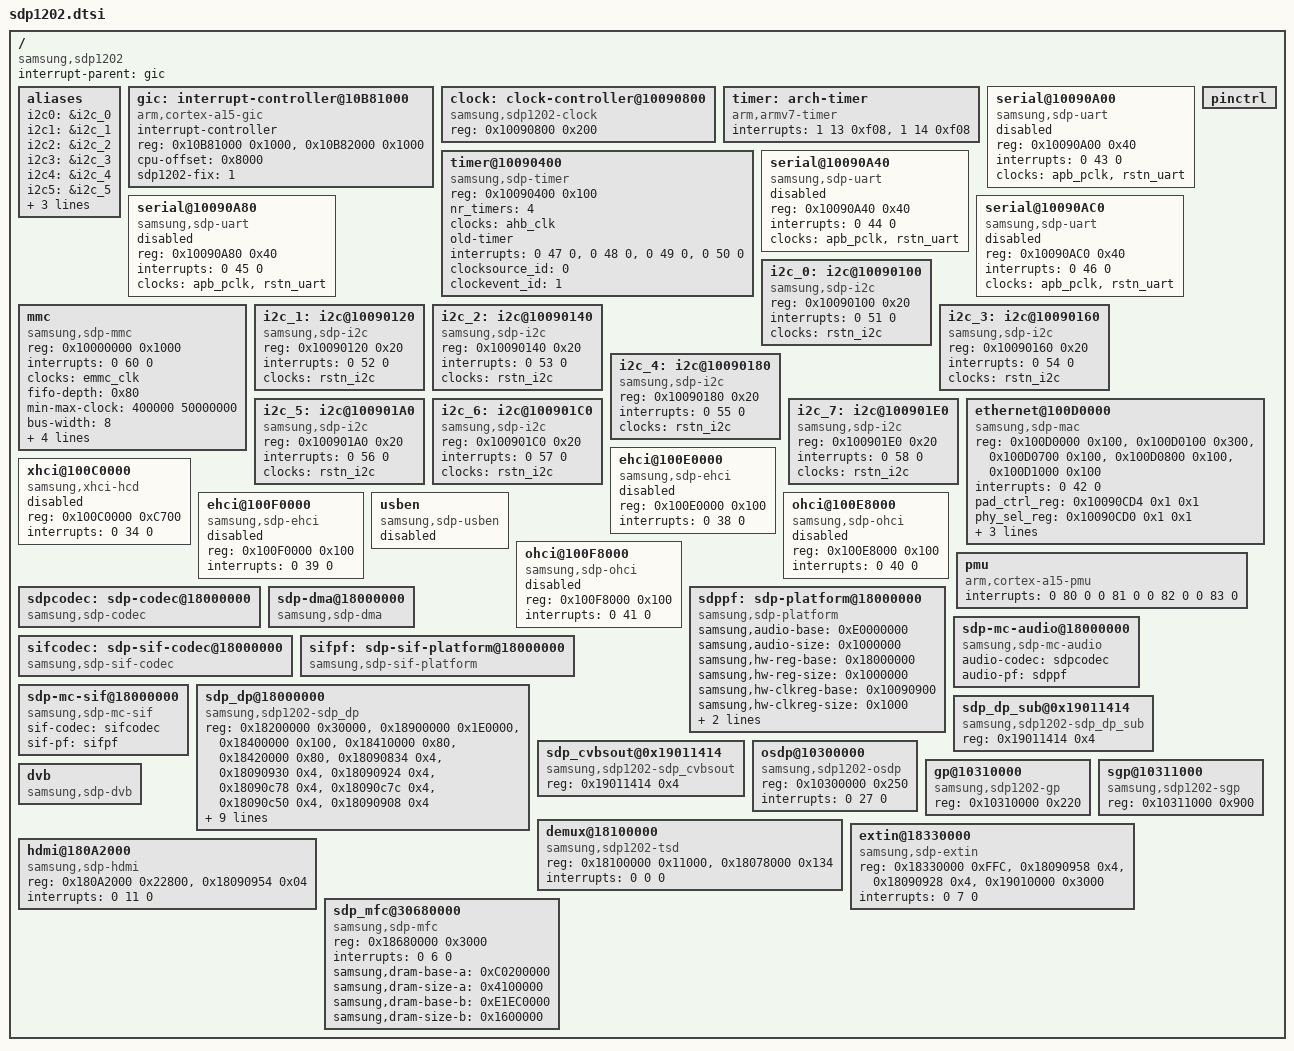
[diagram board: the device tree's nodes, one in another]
/*
 * Copyright (C) 2013 Samsung Electronics Co.Ltd
 *
 * This program is free software; you can redistribute it and/or modify
 * it under the terms of the GNU General Public License version 2 as
 * published by the Free Software Foundation.
 */

#include "sdp.dtsi"
#include "sdp1202-clocks.dtsi"
#include "sdp1202-pinctrl.dtsi"

/ {
	compatible = "samsung,sdp1202";

	interrupt-parent = <&gic>;

	aliases {
		i2c0 = &i2c_0;
		i2c1 = &i2c_1;
		i2c2 = &i2c_2;
		i2c3 = &i2c_3;
		i2c4 = &i2c_4;
		i2c5 = &i2c_5;
		i2c6 = &i2c_6;
		i2c7 = &i2c_7;
		i2c8 = &i2c_15;
	};


	gic: interrupt-controller@10B81000 {
		compatible = "arm,cortex-a15-gic";
		interrupt-controller;
		#interrupt-cells = <3>;
		reg = <0x10B81000 0x1000>, <0x10B82000 0x1000>;
		cpu-offset = <0x8000>;
		sdp1202-fix = <1>;
	};

	clock: clock-controller@10090800 {
		compatible = "samsung,sdp1202-clock";
		reg = <0x10090800 0x200>;
		#clock-cells = <1>;
	};

	timer: arch-timer {
		compatible = "arm,armv7-timer";
		interrupts = <1 13 0xf08>, 
					 <1 14 0xf08>;		    
	};

	timer@10090400 {
		compatible = "samsung,sdp-timer";
		reg = <0x10090400 0x100>;
		nr_timers = <4>;
		clocks = <&ahb_clk>;
		old-timer;
		clock-names = "ahb_clk";
		interrupts = <0 47 0>, <0 48 0>, <0 49 0>, <0 50 0>;
		clocksource_id = <0>;
		clockevent_id = <1>;
	};

	serial@10090A00 {
		compatible = "samsung,sdp-uart";
		reg = <0x10090A00 0x40>;
		interrupts = <0 43 0>;
		clocks = <&apb_pclk>, <&rstn_uart>;
		clock-names = "ahb_clk", "rstn_uart";
		status = "disabled";
	};

	serial@10090A40 {
		compatible = "samsung,sdp-uart";
		reg = <0x10090A40 0x40>;
		interrupts = <0 44 0>;
		clocks = <&apb_pclk>, <&rstn_uart>;
		clock-names = "ahb_clk", "rstn_uart";
		status = "disabled";
	};


	serial@10090A80 {
		compatible = "samsung,sdp-uart";
		reg = <0x10090A80 0x40>;
		interrupts = <0 45 0>;
		clocks = <&apb_pclk>, <&rstn_uart>;
		clock-names = "ahb_clk", "rstn_uart";
		status = "disabled";
	};


	serial@10090AC0 {
		compatible = "samsung,sdp-uart";
		reg = <0x10090AC0 0x40>;
		interrupts = <0 46 0>;
		clocks = <&apb_pclk>, <&rstn_uart>;
		clock-names = "ahb_clk", "rstn_uart";
		status = "disabled";
	};

	pinctrl{
		status = "okay";
	};
	
	mmc {
		compatible = "samsung,sdp-mmc";
		reg = <0x10000000 0x1000>;
		interrupts = <0 60 0>;
		clocks = <&emmc_clk>;
		clock-names = "emmc_clk";
		fifo-depth = <0x80>;
		min-max-clock = <400000 50000000>;

		//initregs = <0x0 0x0 0x0>;

		bus-width=<8>;
		//force-pio-mode;
		hw-reset;

		/* Host Caps */
		non-removable;
		//bus-width-test;
		highspeed;
		ddr50;
	};

	i2c_0: i2c@10090100 {
		#address-cells = <1>;
		#size-cells = <0>;
		compatible = "samsung,sdp-i2c";
		reg = <0x10090100 0x20>;
		interrupts = <0 51 0>;
		clocks = <&rstn_i2c>;
		clock-names = "rstn_i2c";	
	};

	i2c_1: i2c@10090120 {
		#address-cells = <1>;
		#size-cells = <0>;
		compatible = "samsung,sdp-i2c";
		reg = <0x10090120 0x20>;
		interrupts = <0 52 0>;
		clocks = <&rstn_i2c>;
		clock-names = "rstn_i2c";	
	};

	i2c_2: i2c@10090140 {
		#address-cells = <1>;
		#size-cells = <0>;
		compatible = "samsung,sdp-i2c";
		reg = <0x10090140 0x20>;
		interrupts = <0 53 0>;
		clocks = <&rstn_i2c>;
		clock-names = "rstn_i2c";	
	};

	i2c_3: i2c@10090160 {
		#address-cells = <1>;
		#size-cells = <0>;
		compatible = "samsung,sdp-i2c";
		reg = <0x10090160 0x20>;
		interrupts = <0 54 0>;
		clocks = <&rstn_i2c>;
		clock-names = "rstn_i2c";	
	};

	i2c_4: i2c@10090180 {
		#address-cells = <1>;
		#size-cells = <0>;
		compatible = "samsung,sdp-i2c";
		reg = <0x10090180 0x20>;
		interrupts = <0 55 0>;
		clocks = <&rstn_i2c>;
		clock-names = "rstn_i2c";	
	};

	i2c_5: i2c@100901A0 {
		#address-cells = <1>;
		#size-cells = <0>;
		compatible = "samsung,sdp-i2c";
		reg = <0x100901A0 0x20>;
		interrupts = <0 56 0>;
		clocks = <&rstn_i2c>;
		clock-names = "rstn_i2c";
	};

	i2c_6: i2c@100901C0 {
		#address-cells = <1>;
		#size-cells = <0>;
		compatible = "samsung,sdp-i2c";
		reg = <0x100901C0 0x20>;
		interrupts = <0 57 0>;
		clocks = <&rstn_i2c>;
		clock-names = "rstn_i2c";
	};

	i2c_7: i2c@100901E0 {
		#address-cells = <1>;
		#size-cells = <0>;
		compatible = "samsung,sdp-i2c";
		reg = <0x100901E0 0x20>;
		interrupts = <0 58 0>;
		clocks = <&rstn_i2c>;
		clock-names = "rstn_i2c";
	};


	ethernet@100D0000 {
		compatible = "samsung,sdp-mac";
		reg = <0x100D0000 0x100>, 
			<0x100D0100 0x300>,
			<0x100D0700 0x100>,
			<0x100D0800 0x100>,
			<0x100D1000 0x100>;
		interrupts = <0 42 0>;
		pad_ctrl_reg = <0x10090CD4 0x1 0x1>;	/* SRAM select */
		phy_sel_reg = <0x10090CD0 0x1 0x1>;	/* select RGMII register */
		bus_width = <64>;
		phy_mask = <0x00000001>;
		napi_weight = <128>;
	};

    xhci@100C0000 {
		compatible = "samsung,xhci-hcd", "usb-xhci";
        reg = <0x100C0000 0xC700>;
        interrupts = <0 34 0>;
        status = "disabled";
    };

	ehci@100E0000 {
		compatible = "samsung,sdp-ehci", "usb-ehci";
		reg = <0x100E0000 0x100>;
		interrupts = <0 38 0>;
		status = "disabled";
	};

	ehci@100F0000 {
		compatible = "samsung,sdp-ehci", "usb-ehci";
		reg = <0x100F0000 0x100>;
		interrupts = <0 39 0>;
		status = "disabled";
	};

	usben {
		compatible = "samsung,sdp-usben", "usb-ehci";
		status = "disabled";
	};

	ohci@100E8000 {
		compatible = "samsung,sdp-ohci", "usb-ohci";
		reg = <0x100E8000 0x100>;
		interrupts = <0 40 0>;
		status = "disabled";
	};

	ohci@100F8000 {
		compatible = "samsung,sdp-ohci", "usb-ohci";
		reg = <0x100F8000 0x100>;
		interrupts = <0 41 0>;
		status = "disabled";
	};

	pmu	{
		compatible = "arm,cortex-a15-pmu";
		interrupts = <0 80 0
				0 81 0
				0 82 0
				0 83 0>;
	};
	
	/*** AUDIO Entries *****************************************************/
	
	sdpcodec: sdp-codec@18000000	{
		compatible = "samsung,sdp-codec";
		status = "okay";
	};
	
	sdppf: sdp-platform@18000000  {
		compatible = "samsung,sdp-platform";
		samsung,audio-base = <0xE0000000>;
		samsung,audio-size = <0x1000000>;
		samsung,hw-reg-base = <0x18000000>;
		samsung,hw-reg-size = <0x1000000>;
		samsung,hw-clkreg-base = <0x10090900>;
		samsung,hw-clkreg-size = <0x1000>;
		samsung,audio-aio-irq = <0x21>;
		samsung,audio-ae-irq = <0x22>;
		status = "okay";
	};
	
	sdp-dma@18000000  {
		compatible = "samsung,sdp-dma";
	};

	sdp-mc-audio@18000000  {
		compatible = "samsung,sdp-mc-audio";
		audio-codec = <&sdpcodec>;
		audio-pf = <&sdppf>;
	};


	/*ALSA SIF*/
	sifcodec: sdp-sif-codec@18000000	{
		compatible = "samsung,sdp-sif-codec";
		status = "okay";
	};

	sifpf: sdp-sif-platform@18000000  {
		compatible = "samsung,sdp-sif-platform";
		status = "okay";
	};

	sdp-mc-sif@18000000	 {
		compatible = "samsung,sdp-mc-sif";
		sif-codec = <&sifcodec>;
		sif-pf = <&sifpf>;
	};

	/** DP ********************************************************************/	
	sdp_dp@18000000 {
		compatible = "samsung,sdp1202-sdp_dp";
		reg =   <0x18200000 0x30000>,   /* POST */
		    <0x18900000 0x1E0000>,  /* NORMAL */
		    <0x18400000 0x100>,     /* BUS */
		    <0x18410000 0x80>,      /* XMIF-A */
		    <0x18420000 0x80>,      /* XMIF-B */
		    <0x18090834 0x4>,       /* REG_VID_PLL_K */
		    <0x18090930 0x4>,       /* REG_DP_CLK_MUXSEL8 */
		    <0x18090924 0x4>,       /* VID_CLK_MUX_SEL */
		    <0x18090c78 0x4>,       /* REG_DP_LVDSRX0_RESET */
		    <0x18090c7c 0x4>,       /* REG_DP_LVDSRX1_RESET */
		    <0x18090c50 0x4>,		/* REG_DP_PADCTRL_GPIO */
		    <0x18090908 0x4>;		/* REG_DP_CLK_PRESCL_DIV1 */

		interrupts              = <0 4 0>;
		samsung,dp0             = <0 0xE41C0000 0x24C0000>;     /* 42.75 Mbyte*/
		samsung,dp1             = <0 0xC5080000 0x22C0000>;     /* 36.12 Mbyte*/
		samsung,dp2             = <0 0xE69C0000 0xE40000>;      /* 14.125 Mbyte*/
		samsung,dp3             = <0 0x0 0xB80000>;      /* 11.28 Mbyte*/

		samsung,rm_cap_wry      = <0 0xC4E00000 0x200000>;
		samsung,rm_cap_wrc      = <0 0xE7C00000 0x400000>;
		/*samsung,main_cap_wry    = <0 C4E7F000 0x7F000>;*/
		/*samsung,main_cap_wrc    = <0 0x8297D000 0x7F000>;*/
		/*samsung,sub_cap_wry     = <0 0x829FC000 0x7F000>;*/
		/*samsung,sub_cap_wrc     = <0 0x82A7B000 0x7F000>;*/

		samsung,dp_enc_buf      = <0 0xE1880000 0x680000>;
		samsung,dp_ttx_out      = <0 0xC7340000 0x40000>;
		/*samsung,enc0_capt_wry   = <0 0x82E70000 0x7F000>;*/
		/*samsung,enc0_capt_wrc   = <0 0x82EEF000 0x7F000>;*/
		/*samsung,dp_web_enhance_buf   = <0 0xE6680000 0x340000>;*/

	/*	clocks      = <&disp_pclk_nr>,  <&disp_pclk_dcar>,  <&disp_pclk_ipc>,  <&disp_pclk_ucar>,   <&dp_scl_osc_clk>,   <&dp_scl_sub_clk>,   <&dp_scl_pclk>;
		clock-names = "disp_pclk_nr", "disp_pclk_dcar", "disp_pclk_ipc", "disp_pclk_ucar", "dp_scl_osc_clk", "dp_scl_sub_clk", "dp_scl_pclk"; */
	};

	sdp_dp_sub@0x19011414 {
		compatible = "samsung,sdp1202-sdp_dp_sub";
		reg = <0x19011414 0x4>;		/* AFE - OUT-PATH */
	};	

	sdp_cvbsout@0x19011414 {
		compatible = "samsung,sdp1202-sdp_cvbsout";
		reg = <0x19011414 0x4>;		/* AFE - OUT-PATH */
	};

	osdp@10300000 {
		compatible = "samsung,sdp1202-osdp";
		reg =   <0x10300000 0x250>;
		interrupts = <0 27 0>;
	};	

	gp@10310000 {
		compatible = "samsung,sdp1202-gp";
		reg = <0x10310000 0x220>;
	};

	sgp@10311000 {
		compatible = "samsung,sdp1202-sgp";
		reg = <0x10311000 0x900>;
	};
	
	/*******************************************************/
	
	dvb {
		compatible = "samsung,sdp-dvb";
	};

	demux@18100000 {
		compatible = "samsung,sdp1202-tsd";
		reg = <0x18100000 0x11000>, <0x18078000 0x134>;
		reg-names = "tsd", "ci";
		interrupts = <0 0 0>;
	};

	extin@18330000 {
		compatible = "samsung,sdp-extin";
		reg = <0x18330000 0xFFC>, <0x18090958 0x4>, <0x18090928 0x4>, <0x19010000 0x3000>;
		reg-names = "avd-reg", "reg-mp0_sw_rst", "reg-mux_sel6", "afe-reg";
		interrupts = <0 7 0>;
	};

	hdmi@180A2000 {
		compatible = "samsung,sdp-hdmi";
		reg = <0x180A2000 0x22800>, <0x18090954 0x04>;
		reg-names = "hdmi-reg", "hdmi-clk";
		interrupts = <0 11 0>;
	};
	
	/*** DECODER Entries *****************************************************/
	sdp_mfc@30680000 {
		compatible = "samsung,sdp-mfc";
		reg = <0x18680000 0x3000>;
		interrupts = <0 6 0>;
		samsung,dram-base-a = <0xC0200000>;
		samsung,dram-size-a = <0x4100000>;
		samsung,dram-base-b = <0xE1EC0000>;
		samsung,dram-size-b = <0x1600000>;

	};

};
